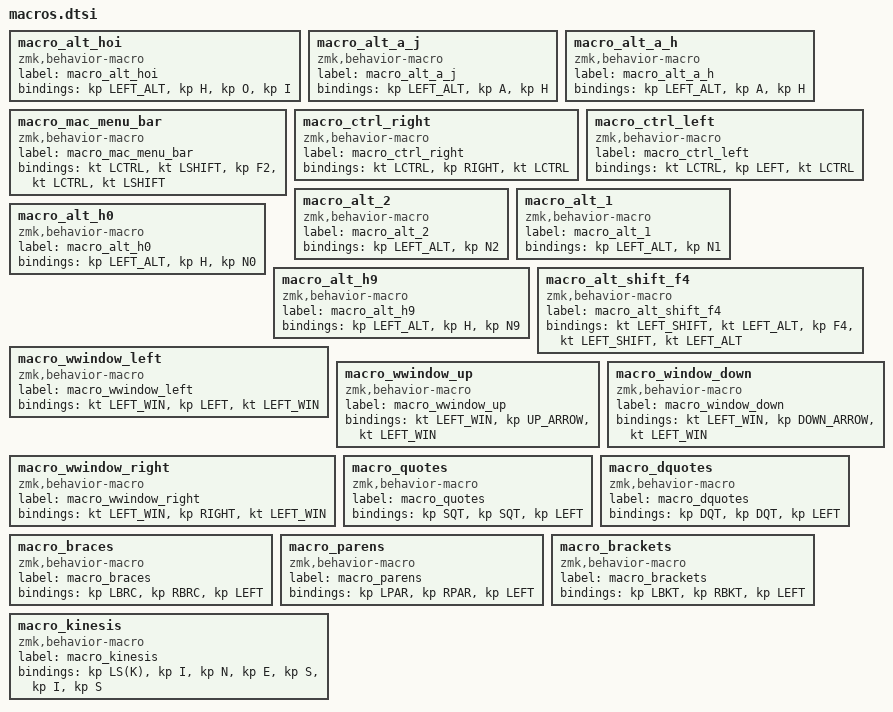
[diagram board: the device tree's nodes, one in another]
macro_alt_hoi: macro_alt_hoi{
compatible = "zmk,behavior-macro";
label = "macro_alt_hoi";
#binding-cells = <0>;
bindings = <&kp LEFT_ALT>, <&kp H>, <&kp O>, <&kp I>;
};
macro_alt_a_j: macro_alt_a_j{
compatible = "zmk,behavior-macro";
label = "macro_alt_a_j";
#binding-cells = <0>;
bindings = <&kp LEFT_ALT>, <&kp A>, <&kp H>;
};
macro_alt_a_h: macro_alt_a_h{
compatible = "zmk,behavior-macro";
label = "macro_alt_a_h";
#binding-cells = <0>;
bindings = <&kp LEFT_ALT>, <&kp A>, <&kp H>;
};
macro_mac_menu_bar: macro_mac_menu_bar{
compatible = "zmk,behavior-macro";
label = "macro_mac_menu_bar";
#binding-cells = <0>;
bindings = <&kt LCTRL>, <&kt LSHIFT>, <&kp F2>, <&kt LCTRL>, <&kt LSHIFT>;
};
macro_ctrl_right: macro_ctrl_right{
compatible = "zmk,behavior-macro";
label = "macro_ctrl_right";
#binding-cells = <0>;
bindings = <&kt LCTRL>, <&kp RIGHT>, <&kt LCTRL>;
};
macro_ctrl_left: macro_ctrl_left{
compatible = "zmk,behavior-macro";
label = "macro_ctrl_left";
#binding-cells = <0>;
bindings = <&kt LCTRL>, <&kp LEFT>, <&kt LCTRL>;
};
macro_alt_2: macro_alt_2{
compatible = "zmk,behavior-macro";
label = "macro_alt_2";
#binding-cells = <0>;
bindings = <&kp LEFT_ALT>, <&kp N2>;
};
macro_alt_1: macro_alt_1{
compatible = "zmk,behavior-macro";
label = "macro_alt_1";
#binding-cells = <0>;
bindings = <&kp LEFT_ALT>, <&kp N1>;
};
macro_alt_h0: macro_alt_h0{
compatible = "zmk,behavior-macro";
label = "macro_alt_h0";
#binding-cells = <0>;
bindings = <&kp LEFT_ALT>, <&kp H>, <&kp N0>;
};
macro_alt_h9: macro_alt_h9{
compatible = "zmk,behavior-macro";
label = "macro_alt_h9";
#binding-cells = <0>;
bindings = <&kp LEFT_ALT>, <&kp H>, <&kp N9>;
};
macro_alt_shift_f4: macro_alt_shift_f4{
compatible = "zmk,behavior-macro";
label = "macro_alt_shift_f4";
#binding-cells = <0>;
bindings = <&kt LEFT_SHIFT>, <&kt LEFT_ALT>, <&kp F4>, <&kt LEFT_SHIFT>, <&kt LEFT_ALT>;
};
macro_wwindow_left: macro_wwindow_left{
compatible = "zmk,behavior-macro";
label = "macro_wwindow_left";
#binding-cells = <0>;
bindings = <&kt LEFT_WIN>, <&kp LEFT>, <&kt LEFT_WIN>;
};
macro_wwindow_up: macro_wwindow_up{
compatible = "zmk,behavior-macro";
label = "macro_wwindow_up";
#binding-cells = <0>;
bindings = <&kt LEFT_WIN>, <&kp UP_ARROW>, <&kt LEFT_WIN>;
};
macro_window_down: macro_window_down{
compatible = "zmk,behavior-macro";
label = "macro_window_down";
#binding-cells = <0>;
bindings = <&kt LEFT_WIN>, <&kp DOWN_ARROW>, <&kt LEFT_WIN>;
};
macro_wwindow_right: macro_wwindow_right{
compatible = "zmk,behavior-macro";
label = "macro_wwindow_right";
#binding-cells = <0>;
bindings = <&kt LEFT_WIN>, <&kp RIGHT>, <&kt LEFT_WIN>;
};
macro_quotes: macro_quotes{
compatible = "zmk,behavior-macro";
label = "macro_quotes";
#binding-cells = <0>;
bindings = <&kp SQT>, <&kp SQT>, <&kp LEFT>;
};
macro_dquotes: macro_dquotes{
compatible = "zmk,behavior-macro";
label = "macro_dquotes";
#binding-cells = <0>;
bindings = <&kp DQT>, <&kp DQT>, <&kp LEFT>;
};
macro_braces: macro_braces{
compatible = "zmk,behavior-macro";
label = "macro_braces";
#binding-cells = <0>;
bindings = <&kp LBRC>, <&kp RBRC>, <&kp LEFT>;
};
macro_parens: macro_parens{
compatible = "zmk,behavior-macro";
label = "macro_parens";
#binding-cells = <0>;
bindings = <&kp LPAR>, <&kp RPAR>, <&kp LEFT>;
};
macro_brackets: macro_brackets{
compatible = "zmk,behavior-macro";
label = "macro_brackets";
#binding-cells = <0>;
bindings = <&kp LBKT>, <&kp RBKT>, <&kp LEFT>;
};
macro_kinesis: macro_kinesis{
compatible = "zmk,behavior-macro";
label = "macro_kinesis";
#binding-cells = <0>;
bindings = <&kp LS(K)>, <&kp I>, <&kp N>, <&kp E>, <&kp S>, <&kp I>, <&kp S>;
};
